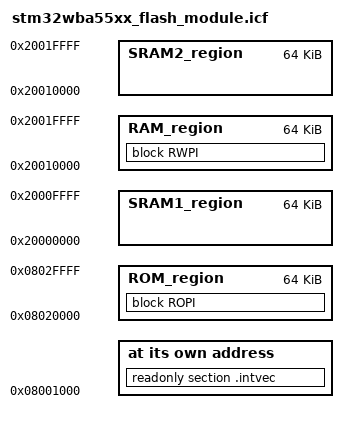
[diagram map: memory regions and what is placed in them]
/*###ICF### Section handled by ICF editor, don't touch! ****/
/*-Editor annotation file-*/
/* IcfEditorFile="$TOOLKIT_DIR$\config\ide\IcfEditor\cortex_v1_0.xml" */
/*-Specials-*/
define symbol __ICFEDIT_intvec_start__ = 0x08001000;
/*-Memory Regions-*/
define symbol __ICFEDIT_region_ROM_start__ = 0x08020000;
define symbol __ICFEDIT_region_ROM_end__   = 0x0802FFFF;
define symbol __ICFEDIT_region_RAM_start__ = 0x20010000;
define symbol __ICFEDIT_region_RAM_end__   = 0x2001FFFF;

/*-Sizes-*/
define symbol __ICFEDIT_size_cstack__ = 0x400;
define symbol __ICFEDIT_size_heap__   = 0x200;
/**** End of ICF editor section. ###ICF###*/

define symbol __region_SRAM1_start__  = 0x20000000;
define symbol __region_SRAM1_end__    = 0x2000FFFF;
define symbol __region_SRAM2_start__  = 0x20010000;
define symbol __region_SRAM2_end__    = 0x2001FFFF;

define memory mem with size = 4G;
define region ROM_region      = mem:[from __ICFEDIT_region_ROM_start__   to __ICFEDIT_region_ROM_end__];
define region RAM_region      = mem:[from __ICFEDIT_region_RAM_start__   to __ICFEDIT_region_RAM_end__];
define region SRAM1_region    = mem:[from __region_SRAM1_start__   to __region_SRAM1_end__];
define region SRAM2_region    = mem:[from __region_SRAM2_start__   to __region_SRAM2_end__];

define block HEAP      with alignment = 8, size = __ICFEDIT_size_heap__     { };

initialize by copy { readwrite };
do not initialize  { section .noinit };

define movable block ROPI with alignment = 4, fixed order
{
  ro object txm_module_preamble.o,
  ro,
  ro data
};

define movable block RWPI with alignment = 8, fixed order, static base
{
  rw,
  block HEAP
};

place at address mem:__ICFEDIT_intvec_start__ { readonly section .intvec };

place in ROM_region   { block ROPI };
place in RAM_region   { block RWPI };
place in SRAM1_region { };
place in SRAM2_region { };
                        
